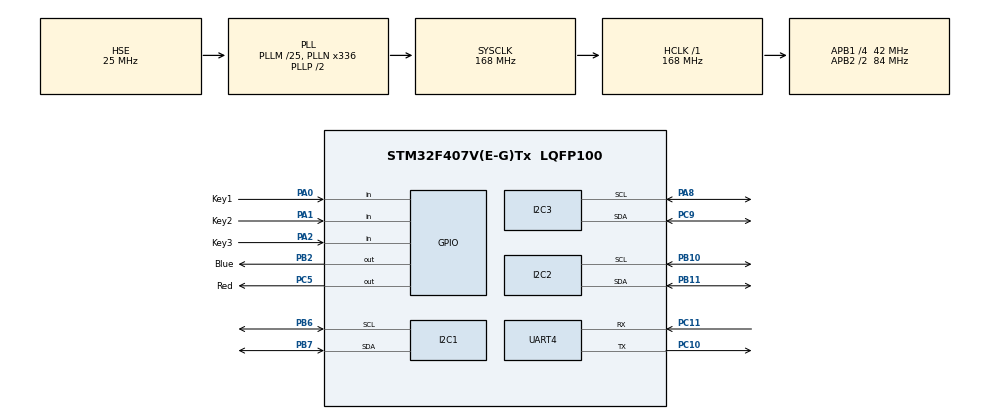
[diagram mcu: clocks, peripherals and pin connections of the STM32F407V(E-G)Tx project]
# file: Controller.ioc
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I2C1.I2C_Mode=I2C_Fast
I2C2.I2C_Mode=I2C_Fast
I2C3.I2C_Mode=I2C_Fast
Mcu.Family=STM32F4
Mcu.Name=STM32F407V(E-G)Tx
Mcu.Package=LQFP100
NVIC.I2C1_ER_IRQn=true\:0\:0\:false\:false\:true\:true\:true\:true
NVIC.I2C1_EV_IRQn=true\:0\:0\:false\:false\:true\:true\:true\:true
NVIC.I2C2_ER_IRQn=true\:0\:0\:false\:false\:true\:true\:true\:true
NVIC.I2C2_EV_IRQn=true\:0\:0\:false\:false\:true\:true\:true\:true
NVIC.I2C3_ER_IRQn=true\:0\:0\:false\:false\:true\:true\:true\:true
NVIC.I2C3_EV_IRQn=true\:0\:0\:false\:false\:true\:true\:true\:true
NVIC.PriorityGroup=NVIC_PRIORITYGROUP_4
NVIC.TIM6_DAC_IRQn=true\:1\:0\:true\:false\:true\:true\:true\:true
NVIC.TIM7_IRQn=true\:1\:0\:true\:false\:true\:true\:true\:true
NVIC.UART4_IRQn=true\:0\:0\:false\:false\:true\:true\:true\:true
PA0-WKUP.GPIO_Label=Key1
PA0-WKUP.GPIO_PuPd=GPIO_PULLDOWN
PA0-WKUP.Signal=GPIO_Input
PA1.GPIO_Label=Key2
PA1.GPIO_PuPd=GPIO_PULLUP
PA1.Signal=GPIO_Input
PA13.Mode=Serial_Wire
PA13.Signal=SYS_JTMS-SWDIO
PA14.Mode=Serial_Wire
PA14.Signal=SYS_JTCK-SWCLK
PA2.GPIO_Label=Key3
PA2.GPIO_PuPd=GPIO_PULLUP
PA2.Signal=GPIO_Input
PA8.Mode=I2C
PA8.Signal=I2C3_SCL
PB10.Mode=I2C
PB10.Signal=I2C2_SCL
PB11.Mode=I2C
PB11.Signal=I2C2_SDA
PB2.GPIO_Label=Blue
PB2.Signal=GPIO_Output
PB6.Mode=I2C
PB6.Signal=I2C1_SCL
PB7.Mode=I2C
PB7.Signal=I2C1_SDA
PC10.Mode=Asynchronous
PC10.Signal=UART4_TX
PC11.Mode=Asynchronous
PC11.Signal=UART4_RX
PC5.GPIO_Label=Red
PC5.Signal=GPIO_Output
PC9.Mode=I2C
PC9.Signal=I2C3_SDA
PH0-OSC_IN.Mode=HSE-External-Oscillator
PH0-OSC_IN.Signal=RCC_OSC_IN
PH1-OSC_OUT.Mode=HSE-External-Oscillator
PH1-OSC_OUT.Signal=RCC_OSC_OUT
ProjectManager.HeapSize=0x200
ProjectManager.StackSize=0x400
ProjectManager.TargetToolchain=Makefile
RCC.48MHZClocksFreq_Value=48000000
RCC.AHBFreq_Value=168000000
RCC.APB1CLKDivider=RCC_HCLK_DIV4
RCC.APB1Freq_Value=42000000
RCC.APB1TimFreq_Value=84000000
RCC.APB2CLKDivider=RCC_HCLK_DIV2
RCC.APB2Freq_Value=84000000
RCC.APB2TimFreq_Value=168000000
RCC.CortexFreq_Value=168000000
RCC.EnbaleCSS=true
RCC.HCLKFreq_Value=168000000
RCC.HSE_VALUE=25000000
RCC.HSI_VALUE=16000000
RCC.LSE_VALUE=32768
RCC.PLLM=25
RCC.PLLN=336
RCC.PLLQ=7
RCC.PLLSourceVirtual=RCC_PLLSOURCE_HSE
RCC.SYSCLKFreq_VALUE=168000000
RCC.SYSCLKSource=RCC_SYSCLKSOURCE_PLLCLK
RCC.VCOOutputFreq_Value=336000000
STMicroelectronics.X-CUBE-ALGOBUILD.1.4.0.LibraryCcDSPOoLibraryJjDSPOoLibrary=true
TIM6.Period=1000-1
TIM6.Prescaler=84-1
TIM7.Period=50000-1
TIM7.Prescaler=84-1
UART4.VirtualMode=Asynchronous
VP_STMicroelectronics.X-CUBE-ALGOBUILD_VS_DSPOoLibraryJjLibrary_1.4.0_1.4.0.Mode=DSPOoLibraryJjLibrary
VP_TIM6_VS_ClockSourceINT.Mode=Enable_Timer
VP_TIM7_VS_ClockSourceINT.Mode=Enable_Timer
board=custom

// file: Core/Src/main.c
/* USER CODE BEGIN Header */
/**
  ******************************************************************************
  * @file           : main.c
  * @brief          : Main program body
  ******************************************************************************
  * @attention
  *
  * Copyright (c) 2026 STMicroelectronics.
  * All rights reserved.
  *
  * This software is licensed under terms that can be found in the LICENSE file
  * in the root directory of this software component.
  * If no LICENSE file comes with this software, it is provided AS-IS.
  *
  ******************************************************************************
  */
/* USER CODE END Header */
#include "main.h"
#include "i2c.h"
#include "tim.h"
#include "usart.h"
#include "gpio.h"

/* USER CODE BEGIN Includes */
#include "debug.h"
#include "encoder.h"
#include "rs232.h"
/* USER CODE END Includes */

void SystemClock_Config(void);

int main(void)
{

  /* MCU Configuration--------------------------------------------------------*/

  /* Reset of all peripherals, Initializes the Flash interface and the Systick. */
  HAL_Init();

  /* Configure the system clock */
  SystemClock_Config();

  /* Initialize all configured peripherals */
  MX_GPIO_Init();
  MX_I2C3_Init();
  MX_TIM6_Init();
  MX_TIM7_Init();
  MX_I2C1_Init();
  MX_I2C2_Init();
  MX_UART4_Init();

  /* Infinite loop */
  /* USER CODE BEGIN WHILE */
  Debug_Init();
  Encoder_Init();
  RS232_Init();
  while (1)
  {
    HAL_Delay(499);
    Debug_Task();
    /* USER CODE END WHILE */

  }
}

void SystemClock_Config(void)
{
  RCC_OscInitTypeDef RCC_OscInitStruct = {0};
  RCC_ClkInitTypeDef RCC_ClkInitStruct = {0};

  /** Configure the main internal regulator output voltage
  */
  __HAL_RCC_PWR_CLK_ENABLE();
  __HAL_PWR_VOLTAGESCALING_CONFIG(PWR_REGULATOR_VOLTAGE_SCALE1);

  /** Initializes the RCC Oscillators according to the specified parameters
  * in the RCC_OscInitTypeDef structure.
  */
  RCC_OscInitStruct.OscillatorType = RCC_OSCILLATORTYPE_HSE;
  RCC_OscInitStruct.HSEState = RCC_HSE_ON;
  RCC_OscInitStruct.PLL.PLLState = RCC_PLL_ON;
  RCC_OscInitStruct.PLL.PLLSource = RCC_PLLSOURCE_HSE;
  RCC_OscInitStruct.PLL.PLLM = 25;
  RCC_OscInitStruct.PLL.PLLN = 336;
  RCC_OscInitStruct.PLL.PLLP = RCC_PLLP_DIV2;
  RCC_OscInitStruct.PLL.PLLQ = 7;
  if (HAL_RCC_OscConfig(&RCC_OscInitStruct) != HAL_OK)
  {
    Error_Handler();
  }

  /** Initializes the CPU, AHB and APB buses clocks
  */
  RCC_ClkInitStruct.ClockType = RCC_CLOCKTYPE_HCLK|RCC_CLOCKTYPE_SYSCLK
                              |RCC_CLOCKTYPE_PCLK1|RCC_CLOCKTYPE_PCLK2;
  RCC_ClkInitStruct.SYSCLKSource = RCC_SYSCLKSOURCE_PLLCLK;
  RCC_ClkInitStruct.AHBCLKDivider = RCC_SYSCLK_DIV1;
  RCC_ClkInitStruct.APB1CLKDivider = RCC_HCLK_DIV4;
  RCC_ClkInitStruct.APB2CLKDivider = RCC_HCLK_DIV2;

  if (HAL_RCC_ClockConfig(&RCC_ClkInitStruct, FLASH_LATENCY_5) != HAL_OK)
  {
    Error_Handler();
  }

  /** Enables the Clock Security System
  */
  HAL_RCC_EnableCSS();
}

void Error_Handler(void)
{
  __disable_irq();
  while (1)
  {
  }
}
